# EZR32LG330F256R60 register map
File version: 4.0.0
CPU: CM3 r2p1, little endian, MPU, no FPU, 3 interrupt priority bits
Registers are 32-bit, read-write, reset 0x0 unless marked. A register's access mark holds for its fields unless they carry their own. Offsets are from the block's base; [hi:lo] are bit positions; {n}, {i} and the like mark numbered series.

## ETM
Base 0xE0041000
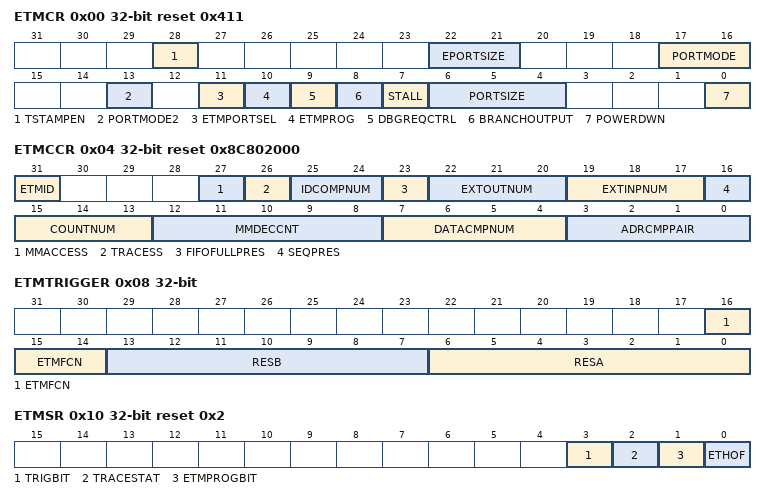
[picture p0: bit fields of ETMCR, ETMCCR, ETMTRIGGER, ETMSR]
0x00 ETMCR reset 0x411 — Main Control Register
  [28] TSTAMPEN — Time Stamp Enable
  [22:21] EPORTSIZE — Port Size[3]
  [17:16] PORTMODE — Port Mode Control
  [13] PORTMODE2
  [11] ETMPORTSEL — ETM Port Selection
  [10] ETMPROG — ETM Programming
  [9] DBGREQCTRL — Debug Request Control
  [8] BRANCHOUTPUT
  [7] STALL — Stall Processor
  [6:4] PORTSIZE — ETM Port Size
  [0] POWERDWN — ETM Control in low power mode
0x04 ETMCCR ro reset 0x8C802000 — Configuration Code Register
  [31] ETMID — ETM ID Register Present
  [27] MMACCESS — Coprocessor and Memeory Access
  [26] TRACESS — Trace Start/Stop Block Present
  [25:24] IDCOMPNUM — Number of context ID Comparators
  [23] FIFOFULLPRES — FIFIO FULL present
  [22:20] EXTOUTNUM — Number of External Output
  [19:17] EXTINPNUM — Number of External Inputs
    0=ZERO (Zero inputs presents); 1=ONE (One inputs presents); 2=TWO (Two inputs presents)
  [16] SEQPRES — Sequencer Present
  [15:13] COUNTNUM — Number of Counters
  [12:8] MMDECCNT — Number of Memeory Map Decoders
  [7:4] DATACMPNUM — Number of Data Value Comparators
  [3:0] ADRCMPPAIR — Number of Address Comparator Pairs
0x08 ETMTRIGGER — ETM Trigger Event Register
  [16:14] ETMFCN — ETM Function
  [13:7] RESB — ETM Resource B
  [6:0] RESA — ETM Resource A
0x10 ETMSR reset 0x2 — ETM Status Register
  [3] TRIGBIT — Trigger Bit
  [2] TRACESTAT — Trace Start/Stop Status
  [1] ETMPROGBIT ro — ETM Programming Bit Status
  [0] ETHOF ro — ETM Overflow
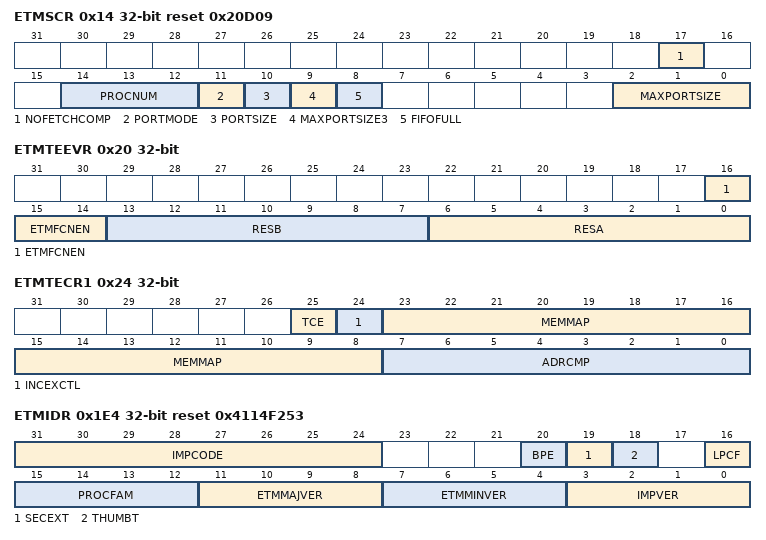
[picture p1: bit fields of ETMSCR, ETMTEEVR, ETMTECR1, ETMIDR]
0x14 ETMSCR ro reset 0x20D09 — ETM System Configuration Register
  [17] NOFETCHCOMP — No Fetch Comparison
  [14:12] PROCNUM — Number of Supported Processros
  [11] PORTMODE — Port Mode Supported
  [10] PORTSIZE — Port Size Supported
  [9] MAXPORTSIZE3
  [8] FIFOFULL — FIFO FULL Supported
  [2:0] MAXPORTSIZE — Maximum Port Size
0x20 ETMTEEVR — ETM TraceEnable Event Register
  [16:14] ETMFCNEN — ETM Function Trace Enable
  [13:7] RESB — ETM Resource B Trace Enable
  [6:0] RESA — ETM Resource A Trace Enable
0x24 ETMTECR1 — ETM Trace control Register
  [25] TCE — Trace Control Enable
  [24] INCEXCTL — Trace Include/Exclude Flag
  [23:8] MEMMAP
  [7:0] ADRCMP — Address Comparator
0x2C ETMFFLR — ETM Fifo Full Level Register
  [7:0] BYTENUM — Bytes left in FIFO
0x140 ETMCNTRLDVR1 — Counter Reload Value
  [15:0] COUNT — Free running counter reload value
0x1E0 ETMSYNCFR reset 0x400 — Synchronisation Frequency Register
  [11:0] FREQ — Synchronisation Frequency Value
0x1E4 ETMIDR ro reset 0x4114F253 — ID Register
  [31:24] IMPCODE — Implementer Code
  [20] BPE — Branch Packet Encoding
  [19] SECEXT — Security Extension Support
  [18] THUMBT — 32-bit Thumb Instruction Tracing
  [16] LPCF — Load PC First
  [15:12] PROCFAM — Implementer Code
  [11:8] ETMMAJVER — Major ETM Architecture Version
  [7:4] ETMMINVER — Minor ETM Architecture Version
  [3:0] IMPVER — Implementation Revision
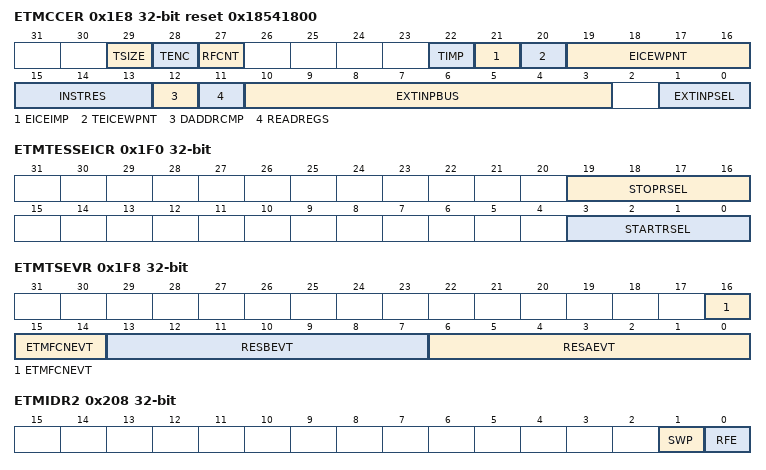
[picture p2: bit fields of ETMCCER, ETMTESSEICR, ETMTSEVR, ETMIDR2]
0x1E8 ETMCCER ro reset 0x18541800 — Configuration Code Extension Register
  [29] TSIZE — Timestamp Size
  [28] TENC — Timestamp Encoding
  [27] RFCNT — Reduced Function Counter
  [22] TIMP — Timestamping Implemented
  [21] EICEIMP — EmbeddedICE Behavior control Implemented
  [20] TEICEWPNT — Trace Sart/Stop Block Uses EmbeddedICE watchpoint inputs
  [19:16] EICEWPNT — EmbeddedICE watchpoint inputs
  [15:13] INSTRES — Instrumentation Resources
  [12] DADDRCMP — Data Address comparisons
  [11] READREGS — Readable Registers
  [10:3] EXTINPBUS — Extended External Input Bus
  [1:0] EXTINPSEL — Extended External Input Selectors
0x1F0 ETMTESSEICR — TraceEnable Start/Stop EmbeddedICE Control Register
  [19:16] STOPRSEL — Stop Resource Selection
  [3:0] STARTRSEL — Stop Resource Selection
0x1F8 ETMTSEVR — Timestamp Event Register
  [16:14] ETMFCNEVT — ETM Function Event
  [13:7] RESBEVT — ETM Resource B Event
  [6:0] RESAEVT — ETM Resource A Event
0x200 ETMTRACEIDR — CoreSight Trace ID Register
  [6:0] TRACEID
0x208 ETMIDR2 ro — ETM ID Register 2
  [1] SWP — SWP Transfer Order
  [0] RFE — RFE Transfer Order
0x314 ETMPDSR ro reset 0x1 — Device Power-down Status Register
  [0] ETMUP — ETM Powered Up
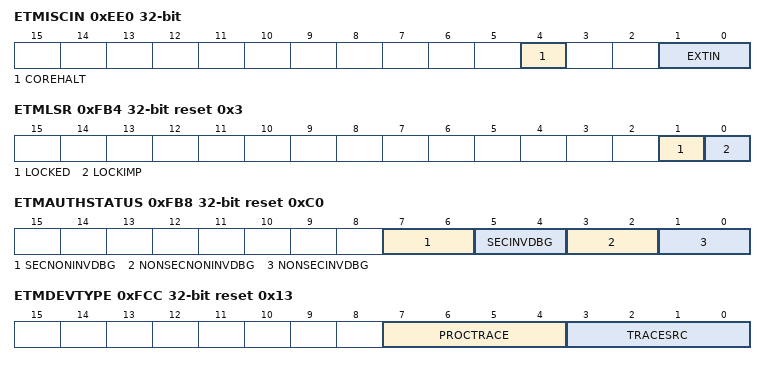
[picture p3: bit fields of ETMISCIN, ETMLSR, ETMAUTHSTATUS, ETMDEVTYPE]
0xEE0 ETMISCIN — Integration Test Miscellaneous Inputs Register
  [4] COREHALT
  [1:0] EXTIN — EXTIN Value
0xEE8 ITTRIGOUT wo — Integration Test Trigger Out Register
  [0] TRIGGEROUT — Trigger output value
0xEF0 ETMITATBCTR2 ro reset 0x1 — ETM Integration Test ATB Control 2 Register
  [0] ATREADY — ATREADY Input Value
0xEF8 ETMITATBCTR0 wo — ETM Integration Test ATB Control 0 Register
  [0] ATVALID — ATVALID Output Value
0xF00 ETMITCTRL — ETM Integration Control Register
  [0] ITEN — Integration Mode Enable
0xFA0 ETMCLAIMSET reset 0xF — ETM Claim Tag Set Register
  [7:0] SETTAG — Tag Bits
0xFA4 ETMCLAIMCLR — ETM Claim Tag Clear Register
  [0] CLRTAG — Tag Bits
0xFB0 ETMLAR — ETM Lock Access Register
  [0] KEY — Key Value
0xFB4 ETMLSR ro reset 0x3 — Lock Status Register
  [1] LOCKED — ETM locked
  [0] LOCKIMP — ETM Locking Implemented
0xFB8 ETMAUTHSTATUS ro reset 0xC0 — ETM Authentication Status Register
  [7:6] SECNONINVDBG — Secure non-invasive Debug Status
  [5:4] SECINVDBG — Secure invasive Debug Status
  [3:2] NONSECNONINVDBG — Non-secure non-invasive Debug Status
    2=DISABLE (Non-secure non-invasive debug disable); 3=ENABLE (Non-secure non-invasive debug enable)
  [1:0] NONSECINVDBG — Non-secure invasive Debug Status
0xFCC ETMDEVTYPE ro reset 0x13 — CoreSight Device Type Register
  [7:4] PROCTRACE — Processor Trace
  [3:0] TRACESRC — Trace Source
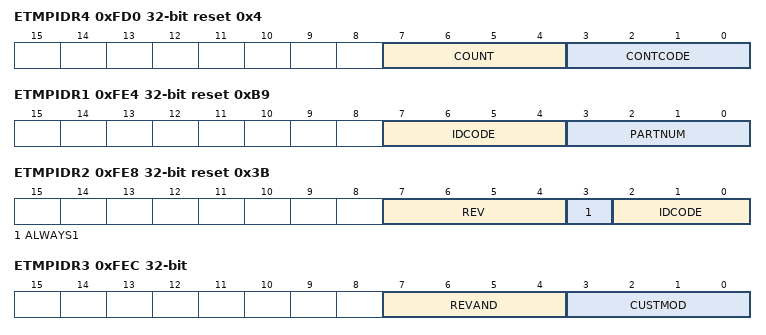
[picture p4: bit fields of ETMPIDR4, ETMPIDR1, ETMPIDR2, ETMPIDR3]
0xFD0 ETMPIDR4 ro reset 0x4 — Peripheral ID4 Register
  [7:4] COUNT — 4KB Count
  [3:0] CONTCODE — JEP106 Continuation Code
{0xFC0+4i} ETMPIDR{i} wo reset not defined (i=5..7) — Peripheral ID{i} Register
0xFE0 ETMPIDR0 ro reset 0x24 — Peripheral ID0 Register
  [7:0] PARTNUM — Part Number
0xFE4 ETMPIDR1 ro reset 0xB9 — Peripheral ID1 Register
  [7:4] IDCODE — JEP106 Identity Code
  [3:0] PARTNUM — Part Number
0xFE8 ETMPIDR2 ro reset 0x3B — Peripheral ID2 Register
  [7:4] REV — Revision
  [3] ALWAYS1
  [2:0] IDCODE — JEP106 Identity Code
0xFEC ETMPIDR3 ro — Peripheral ID3 Register
  [7:4] REVAND
  [3:0] CUSTMOD — Customer Modified
0xFF0 ETMCIDR0 ro reset 0xD — Component ID0 Register
  [7:0] PREAMB — CoreSight Preamble
0xFF4 ETMCIDR1 ro reset 0x90 — Component ID1 Register
  [7:0] PREAMB — CoreSight Preamble
0xFF8 ETMCIDR2 ro reset 0x5 — Component ID2 Register
  [7:0] PREAMB — CoreSight Preamble
0xFFC ETMCIDR3 ro reset 0xB1 — Component ID3 Register
  [7:0] PREAMB — CoreSight Preamble

## Notices in the file
# License
Copyright 2021 Silicon Laboratories Inc. www.silabs.com
SPDX-License-Identifier: Zlib
The licensor of this software is Silicon Laboratories Inc.
This software is provided 'as-is', without any express or implied
warranty. In no event will the authors be held liable for any damages
arising from the use of this software.
Permission is granted to anyone to use this software for any purpose,
including commercial applications, and to alter it and redistribute it
freely, subject to the following restrictions:
1. The origin of this software must not be misrepresented; you must not
claim that you wrote the original software. If you use this software
in a product, an acknowledgment in the product documentation would be
appreciated but is not required.
2. Altered source versions must be plainly marked as such, and must not be
misrepresented as being the original software.
3. This notice may not be removed or altered from any source distribution.
